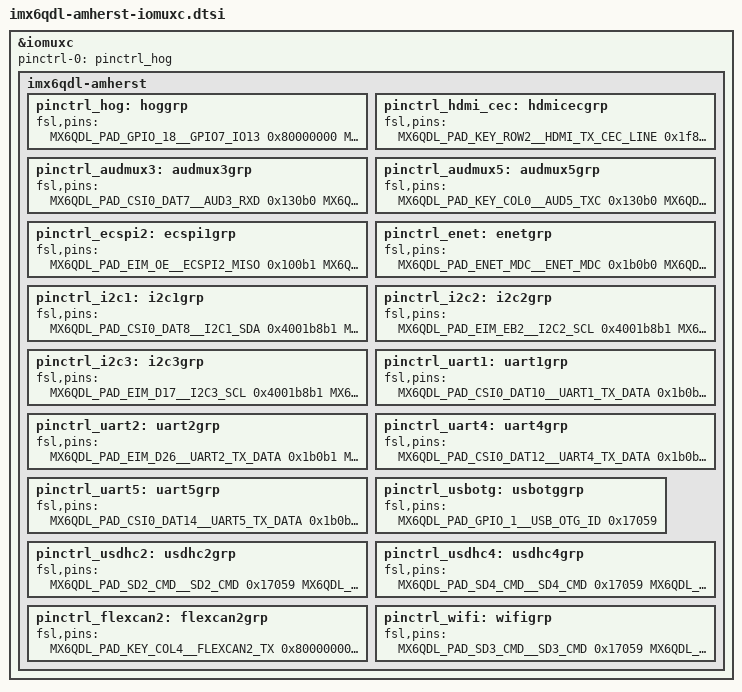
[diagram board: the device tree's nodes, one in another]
&iomuxc {
	pinctrl-names = "default";
	pinctrl-0 = <&pinctrl_hog>;

	imx6qdl-amherst {
		pinctrl_hog: hoggrp {
			fsl,pins = <
				/* SD card power enable */
				MX6QDL_PAD_GPIO_18__GPIO7_IO13		0x80000000

				/* WiFi Power Down Active Low */
				MX6QDL_PAD_SD3_DAT4__GPIO7_IO01		0x80000000

				/* WiFi Reset Active Low */
				MX6QDL_PAD_SD3_RST__GPIO7_IO08		0x80000000

				/* Clock for WiFi and SGTL5000 */
				MX6QDL_PAD_GPIO_0__CCM_CLKO1    	0x130b0
				MX6QDL_PAD_GPIO_0__CCM_CLKO1		0x000b0		/* SGTL5000 sys_mclk */
				/*MX6QDL_PAD_GPIO_0__CCM_CLKO1    	0x80000000*/

/*				MX6QDL_PAD_NANDF_D2__GPIO2_IO02 0x80000000
				MX6QDL_PAD_NANDF_D3__GPIO2_IO03 0x80000000
				MX6QDL_PAD_GPIO_0__CCM_CLKO1    0x130b0
				MX6QDL_PAD_NANDF_CLE__GPIO6_IO07 0x80000000
				MX6QDL_PAD_NANDF_ALE__GPIO6_IO08 0x80000000
				MX6QDL_PAD_ENET_TXD1__GPIO1_IO29 0x80000000
				MX6QDL_PAD_EIM_D22__GPIO3_IO22  0x80000000
				MX6QDL_PAD_ENET_CRS_DV__GPIO1_IO25 0x80000000
				MX6QDL_PAD_EIM_D26__GPIO3_IO26 0x80000000
				MX6QDL_PAD_EIM_CS1__GPIO2_IO24 0x80000000
				MX6QDL_PAD_ENET_RXD0__GPIO1_IO27 0x80000000
				MX6QDL_PAD_EIM_A25__GPIO5_IO02 0x80000000
				MX6QDL_PAD_EIM_D23__GPIO3_IO23 0x80000000
				MX6QDL_PAD_EIM_EB3__GPIO2_IO31 0x80000000
				MX6QDL_PAD_SD1_CMD__GPIO1_IO18 0x80000000
				MX6QDL_PAD_EIM_D16__GPIO3_IO16 0x80000000
				MX6QDL_PAD_SD3_RST__GPIO7_IO08	0x80000000
				MX6QDL_PAD_GPIO_9__GPIO1_IO09 	0x80000000
				MX6QDL_PAD_EIM_DA9__GPIO3_IO09 0x80000000
				MX6QDL_PAD_GPIO_1__WDOG2_B 0x80000000
				MX6QDL_PAD_NANDF_CS0__GPIO6_IO11 0x80000000
				MX6QDL_PAD_NANDF_CS1__GPIO6_IO14 0x80000000
				MX6QDL_PAD_NANDF_CS2__GPIO6_IO15 0x80000000
				MX6QDL_PAD_NANDF_CS3__GPIO6_IO16 0x80000000*/
			>;
		};

		pinctrl_hdmi_cec: hdmicecgrp {
			fsl,pins = <
				MX6QDL_PAD_KEY_ROW2__HDMI_TX_CEC_LINE 0x1f8b0
			>;
		};

		pinctrl_audmux3: audmux3grp {
			fsl,pins = <
				MX6QDL_PAD_CSI0_DAT7__AUD3_RXD		0x130b0
				MX6QDL_PAD_CSI0_DAT4__AUD3_TXC		0x130b0
				MX6QDL_PAD_CSI0_DAT5__AUD3_TXD		0x110b0
				MX6QDL_PAD_CSI0_DAT6__AUD3_TXFS		0x130b0
			>;
		};

		pinctrl_audmux5: audmux5grp {
			fsl,pins = <
				MX6QDL_PAD_KEY_COL0__AUD5_TXC	  	0x130b0
				MX6QDL_PAD_KEY_ROW0__AUD5_TXD	  	0x130b0
				MX6QDL_PAD_KEY_COL1__AUD5_TXFS	  	0x130b0
				MX6QDL_PAD_KEY_ROW1__AUD5_RXD	  	0x130b0
			>;
		};

		pinctrl_ecspi2: ecspi1grp {
			fsl,pins = <
				MX6QDL_PAD_EIM_OE__ECSPI2_MISO 		0x100b1
				MX6QDL_PAD_EIM_CS1__ECSPI2_MOSI 	0x100b1
				MX6QDL_PAD_EIM_CS0__ECSPI2_SCLK 	0x100b1
			>;
		};

		pinctrl_enet: enetgrp {
			fsl,pins = <
				MX6QDL_PAD_ENET_MDC__ENET_MDC         	0x1b0b0
				MX6QDL_PAD_ENET_MDIO__ENET_MDIO       	0x1b0b0
				MX6QDL_PAD_ENET_CRS_DV__ENET_RX_EN    	0x80000000
				MX6QDL_PAD_ENET_RXD0__ENET_RX_DATA0   	0x80000000
				MX6QDL_PAD_ENET_RXD1__ENET_RX_DATA1   	0x80000000
				MX6QDL_PAD_ENET_TX_EN__ENET_TX_EN     	0x80000000
				MX6QDL_PAD_ENET_TXD0__ENET_TX_DATA0   	0x80000000
				MX6QDL_PAD_ENET_TXD1__ENET_TX_DATA1   	0x80000000
				MX6QDL_PAD_ENET_REF_CLK__ENET_TX_CLK  	0x80000000
				MX6QDL_PAD_ENET_RX_ER__ENET_RX_ER     	0x80000000
				MX6QDL_PAD_GPIO_3__GPIO1_IO03         	0x80000000
				MX6QDL_PAD_KEY_COL2__GPIO4_IO10       	0x80000000
				MX6QDL_PAD_GPIO_16__ENET_REF_CLK      	0x4001b0a8
			>;
		};

		pinctrl_i2c1: i2c1grp {
			fsl,pins = <
				MX6QDL_PAD_CSI0_DAT8__I2C1_SDA 		0x4001b8b1
				MX6QDL_PAD_CSI0_DAT9__I2C1_SCL 		0x4001b8b1
			>;
		};

		pinctrl_i2c2: i2c2grp {
			fsl,pins = <
				MX6QDL_PAD_EIM_EB2__I2C2_SCL 		0x4001b8b1
				MX6QDL_PAD_EIM_D16__I2C2_SDA 		0x4001b8b1
			 >;
		};

		pinctrl_i2c3: i2c3grp {
			fsl,pins = <
				MX6QDL_PAD_EIM_D17__I2C3_SCL 		0x4001b8b1
				MX6QDL_PAD_EIM_D18__I2C3_SDA 		0x4001b8b1
			 >;
		};

		pinctrl_uart1: uart1grp {
			fsl,pins = <
				MX6QDL_PAD_CSI0_DAT10__UART1_TX_DATA 	0x1b0b1
				MX6QDL_PAD_CSI0_DAT11__UART1_RX_DATA 	0x1b0b1
			>;
		};

		pinctrl_uart2: uart2grp {
			fsl,pins = <
				MX6QDL_PAD_EIM_D26__UART2_TX_DATA   	0x1b0b1
				MX6QDL_PAD_EIM_D27__UART2_RX_DATA   	0x1b0b1
				MX6QDL_PAD_EIM_D28__UART2_CTS_B     	0x1b0b1
				MX6QDL_PAD_EIM_D29__UART2_RTS_B     	0x1b0b1
			>;
		};

		pinctrl_uart4: uart4grp {
			fsl,pins = <
				MX6QDL_PAD_CSI0_DAT12__UART4_TX_DATA 	0x1b0b1
				MX6QDL_PAD_CSI0_DAT13__UART4_RX_DATA 	0x1b0b1
				MX6QDL_PAD_CSI0_DAT17__UART4_CTS_B 	0x1b0b1
				MX6QDL_PAD_CSI0_DAT16__UART4_RTS_B 	0x1b0b1
			>;
		};

		pinctrl_uart5: uart5grp {
			fsl,pins = <
				MX6QDL_PAD_CSI0_DAT14__UART5_TX_DATA 	0x1b0b1
				MX6QDL_PAD_CSI0_DAT15__UART5_RX_DATA 	0x1b0b1
				MX6QDL_PAD_CSI0_DAT19__UART5_CTS_B 	0x1b0b1
				MX6QDL_PAD_CSI0_DAT18__UART5_RTS_B 	0x1b0b1
			>;
		};

		pinctrl_usbotg: usbotggrp {
			fsl,pins = <
				MX6QDL_PAD_GPIO_1__USB_OTG_ID 		0x17059
			>;
		};

		pinctrl_usdhc2: usdhc2grp {
			fsl,pins = <
				MX6QDL_PAD_SD2_CMD__SD2_CMD    		0x17059
				MX6QDL_PAD_SD2_CLK__SD2_CLK    		0x10059
				MX6QDL_PAD_GPIO_4__GPIO1_IO04  		0x17059
				MX6QDL_PAD_GPIO_2__GPIO1_IO02  		0x17059
				MX6QDL_PAD_SD2_DAT0__SD2_DATA0 		0x17059
				MX6QDL_PAD_SD2_DAT1__SD2_DATA1 		0x17059
				MX6QDL_PAD_SD2_DAT2__SD2_DATA2 		0x17059
				MX6QDL_PAD_SD2_DAT3__SD2_DATA3 		0x17059
			>;
		};

		pinctrl_usdhc4: usdhc4grp {
			fsl,pins = <
				MX6QDL_PAD_SD4_CMD__SD4_CMD    		0x17059
				MX6QDL_PAD_SD4_CLK__SD4_CLK    		0x10059
				MX6QDL_PAD_SD4_DAT0__SD4_DATA0 		0x17059
				MX6QDL_PAD_SD4_DAT1__SD4_DATA1 		0x17059
				MX6QDL_PAD_SD4_DAT2__SD4_DATA2 		0x17059
				MX6QDL_PAD_SD4_DAT3__SD4_DATA3 		0x17059
				MX6QDL_PAD_SD4_DAT4__SD4_DATA4 		0x17059
				MX6QDL_PAD_SD4_DAT5__SD4_DATA5 		0x17059
				MX6QDL_PAD_SD4_DAT6__SD4_DATA6 		0x17059
				MX6QDL_PAD_SD4_DAT7__SD4_DATA7 		0x17059
			>;
		};

		pinctrl_flexcan2: flexcan2grp {
			fsl,pins = <
				MX6QDL_PAD_KEY_COL4__FLEXCAN2_TX 	0x80000000
				MX6QDL_PAD_KEY_ROW4__FLEXCAN2_RX 	0x80000000
			>;
		};

		pinctrl_wifi: wifigrp {
			fsl,pins = <
				/* usdhc3 */
				MX6QDL_PAD_SD3_CMD__SD3_CMD    		0x17059
				MX6QDL_PAD_SD3_CLK__SD3_CLK    		0x10059
				MX6QDL_PAD_SD3_DAT0__SD3_DATA0 		0x17059
				MX6QDL_PAD_SD3_DAT1__SD3_DATA1 		0x17059
				MX6QDL_PAD_SD3_DAT2__SD3_DATA2 		0x17059
				MX6QDL_PAD_SD3_DAT3__SD3_DATA3 		0x17059
			>;
		};
	};
};
